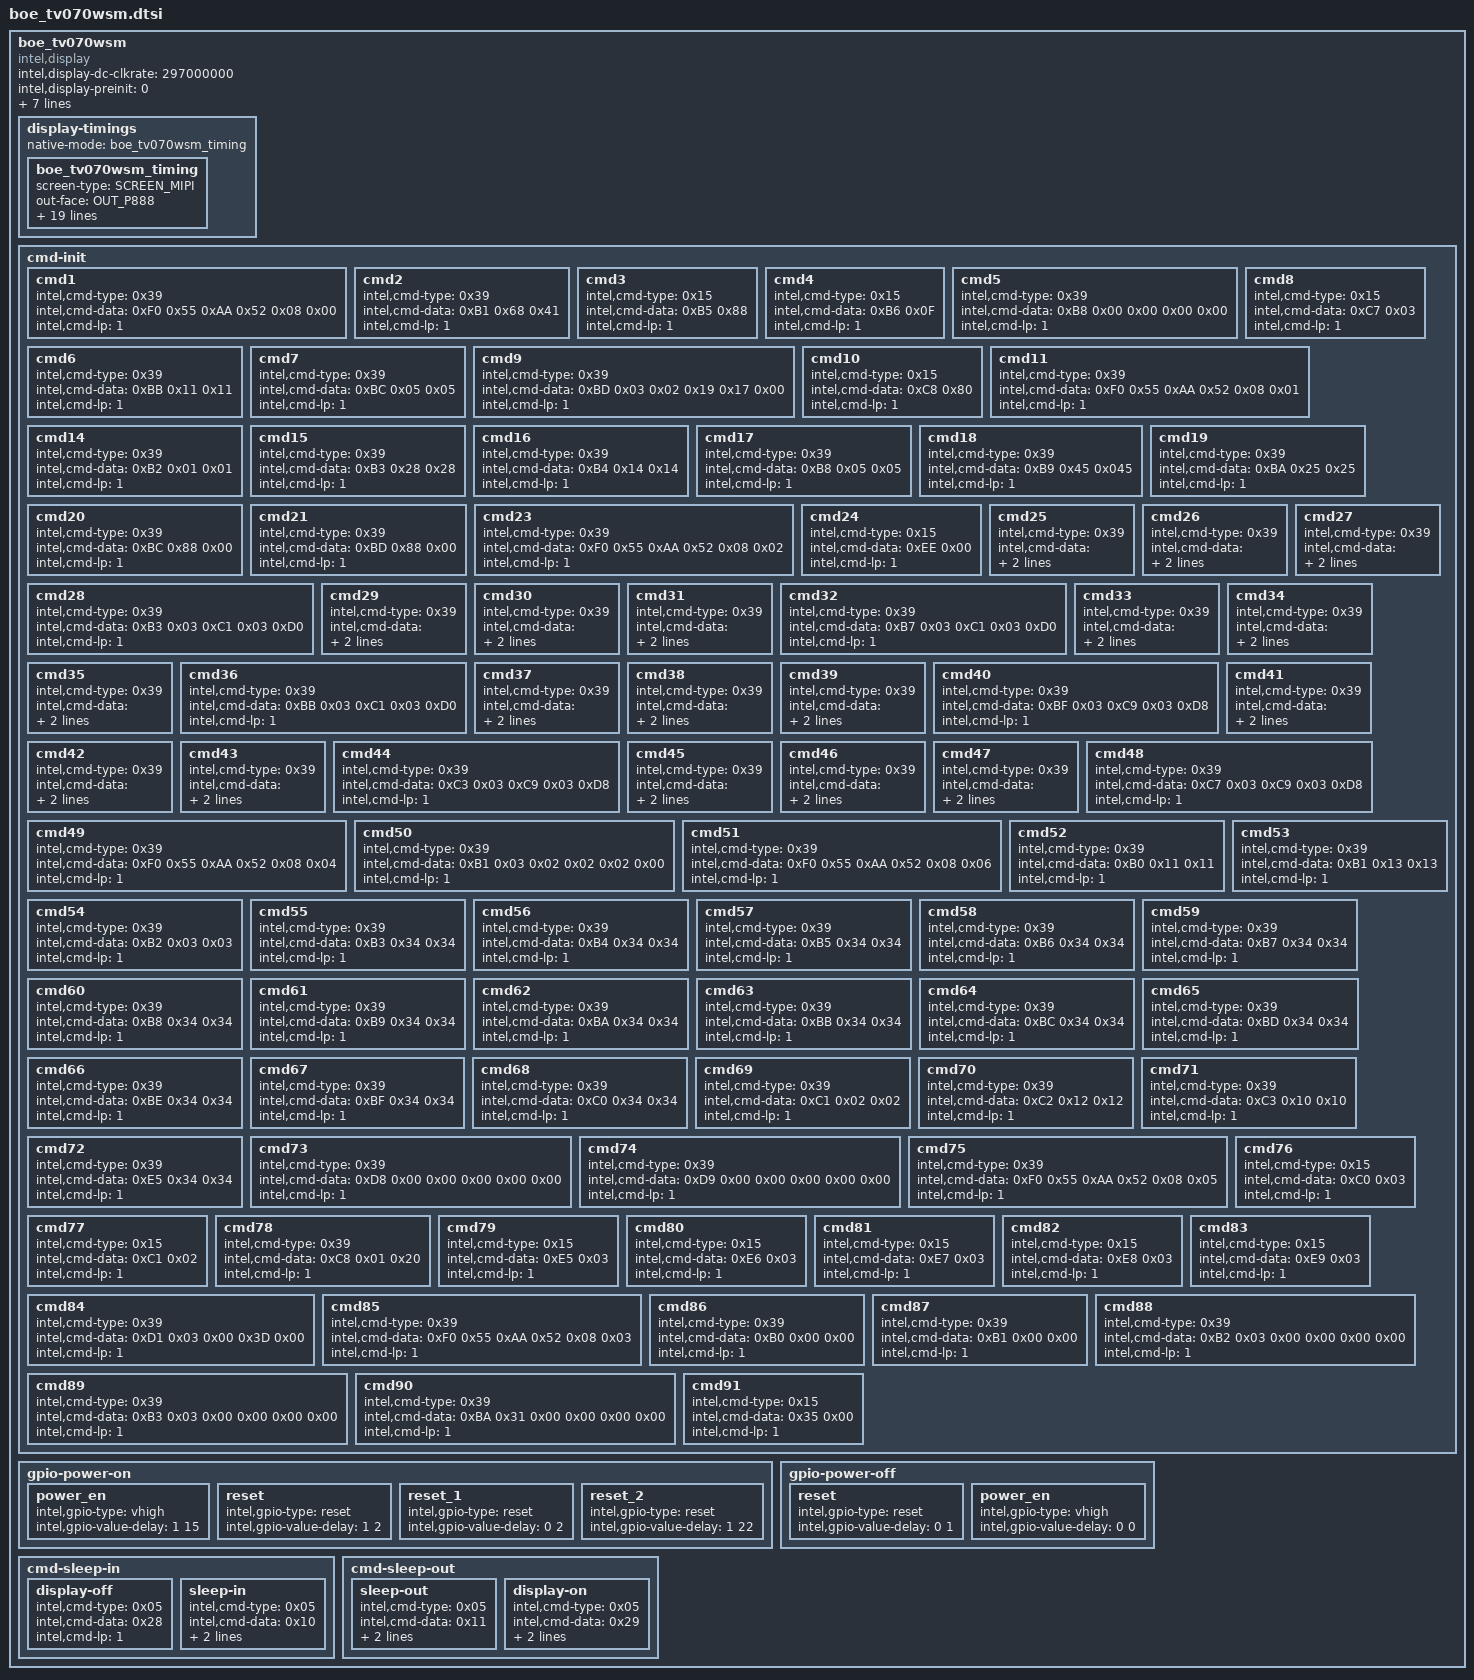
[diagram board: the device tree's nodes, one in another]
/*
 * definition at "include/dt-bindings/sofiafb/sofia_fb.h"
 */


boe_tv070wsm {
	compatible = "intel,display";
	intel,display-dc-clkrate = <297000000>;
	intel,display-preinit = <0>;
	intel,display-ramless = <1>;
	intel,display-fps = <60>;
	intel,display-vid-mode = "burst";
	intel,display-vid-id = <0>;
	intel,display-if-nblanes = <4>;
	intel,display-eot = <1>;
	intel,display-gate = <1>;

	display-timings {
		native-mode = <&boe_tv070wsm_timing>;
		boe_tv070wsm_timing: boe_tv070wsm_timing {
			screen-type = <SCREEN_MIPI>;
			out-face    = <OUT_P888>;
			color-mode = <COLOR_RGB>;
			width = <89>;
			height = <152>;
			clock-frequency = <42432000>;
			hactive = <600>;
			vactive = <1024>;
			hback-porch = <36>;
			hfront-porch = <20>;
			vback-porch = <8>;
			vfront-porch = <6>;
			hsync-len = <24>;
			vsync-len = <2>;
			hsync-active = <0>;
			vsync-active = <0>;
			de-active = <0>;
			pixelclk-active = <0>;
			swap-rb = <0>;
			swap-rg = <0>;
			swap-gb = <0>;
		};
	};
	cmd-init{
		cmd1 {
			intel,cmd-type = <0x39>;
			intel,cmd-data = <0xF0 0x55 0xAA 0x52 0x08 0x00>;
		        intel,cmd-lp = <1>;
		};
		cmd2 {
			intel,cmd-type = <0x39>;
			intel,cmd-data = <0xB1 0x68 0x41>;
			intel,cmd-lp = <1>;
		};
		cmd3 {
			intel,cmd-type = <0x15>;
			intel,cmd-data = <0xB5 0x88>;
			intel,cmd-lp = <1>;
		};
		cmd4 {
			intel,cmd-type = <0x15>;
			intel,cmd-data = <0xB6 0x0F>;
			intel,cmd-lp = <1>;
		};
		cmd5 {
			intel,cmd-type = <0x39>;
			intel,cmd-data = <0xB8 0x00 0x00 0x00 0x00>;
			intel,cmd-lp = <1>;
		};
		cmd6 {
			intel,cmd-type = <0x39>;
			intel,cmd-data = <0xBB 0x11 0x11>;
			intel,cmd-lp = <1>;
		};
		cmd7 {
			intel,cmd-type = <0x39>;
			intel,cmd-data = <0xBC 0x05 0x05>;
			intel,cmd-lp = <1>;
		};
		cmd8 {
			intel,cmd-type = <0x15>;
			intel,cmd-data = <0xC7 0x03>;
			intel,cmd-lp = <1>;
		};
		cmd9 {
			intel,cmd-type = <0x39>;
			intel,cmd-data = <0xBD 0x03 0x02 0x19 0x17 0x00>;
			intel,cmd-lp = <1>;
		};
		cmd10 {
			intel,cmd-type = <0x15>;
			intel,cmd-data = <0xC8 0x80>;
			intel,cmd-lp = <1>;
		};
		cmd11 {
			intel,cmd-type = <0x39>;
			intel,cmd-data = <0xF0 0x55 0xAA 0x52 0x08 0x01>;
			intel,cmd-lp = <1>;
		};
		cmd14 {
			intel,cmd-type = <0x39>;
			intel,cmd-data = <0xB2 0x01 0x01>;
			intel,cmd-lp = <1>;
		};
		cmd15 {
			intel,cmd-type = <0x39>;
			intel,cmd-data = <0xB3 0x28 0x28>;
			intel,cmd-lp = <1>;
		};
		cmd16 {
			intel,cmd-type = <0x39>;
			intel,cmd-data = <0xB4 0x14 0x14>;
			intel,cmd-lp = <1>;
		};
		cmd17 {
			intel,cmd-type = <0x39>;
			intel,cmd-data = <0xB8 0x05 0x05>;
			intel,cmd-lp = <1>;
		};
		cmd18 {
			intel,cmd-type = <0x39>;
			intel,cmd-data = <0xB9 0x45 0x045>;
			intel,cmd-lp = <1>;
		};
		cmd19 {
			intel,cmd-type = <0x39>;
			intel,cmd-data = <0xBA 0x25 0x25>;
			intel,cmd-lp = <1>;
		};
		cmd20 {
			intel,cmd-type = <0x39>;
			intel,cmd-data = <0xBC 0x88 0x00>;
			intel,cmd-lp = <1>;
		};
		cmd21 {
			intel,cmd-type = <0x39>;
			intel,cmd-data = <0xBD 0x88 0x00>;
			intel,cmd-lp = <1>;
		};
		cmd23 {
			intel,cmd-type = <0x39>;
			intel,cmd-data = <0xF0 0x55 0xAA 0x52 0x08 0x02>;
			intel,cmd-lp = <1>;
		};
		cmd24 {
			intel,cmd-type = <0x15>;
			intel,cmd-data = <0xEE 0x00>;
			intel,cmd-lp = <1>;
		};
		cmd25 {
			intel,cmd-type = <0x39>;
			intel,cmd-data = <0xB0 0x00 0x4E 0x00 0x51 0x00 0x77 0x00
			0x8F 0x00 0xA3 0x00 0xC6 0x00 0xE0
			0x01 0x12>;
			intel,cmd-lp = <1>;
		};
		cmd26 {
			intel,cmd-type = <0x39>;
			intel,cmd-data = <0xB1 0x01 0x34 0x01 0x6D 0x01 0x97 0x01
			0xDC 0x02 0x13 0x02 0x14 0x02 0x47
			0x02 0x7D>;
			intel,cmd-lp = <1>;
		};
		cmd27 {
			intel,cmd-type = <0x39>;
			intel,cmd-data = <0xB2 0x02 0xA5 0x02 0xD7 0x02 0xFA 0x03
			0x27 0x03 0x44 0x03 0x6D 0x03 0x8B
			0x03 0xA2>;
			intel,cmd-lp = <1>;
		};
		cmd28 {
			intel,cmd-type = <0x39>;
			intel,cmd-data = <0xB3 0x03 0xC1 0x03 0xD0>;
			intel,cmd-lp = <1>;
		};
		cmd29 {
			intel,cmd-type = <0x39>;
			intel,cmd-data = <0xB4 0x00 0x4E 0x00 0x51 0x00 0x77 0x00
			0x8F 0x00 0xA3 0x00 0xC6 0x00 0xE0
			0x01 0x12>;
			intel,cmd-lp = <1>;
		};
		cmd30 {
			intel,cmd-type = <0x39>;
			intel,cmd-data = <0xB5 0x01 0x34 0x01 0x6B 0x01 0x97 0x01
			0xDC 0x02 0x13 0x02 0x14 0x02 0x47
			0x02 0x7D>;
			intel,cmd-lp = <1>;
		};
		cmd31 {
			intel,cmd-type = <0x39>;
			intel,cmd-data = <0xB6 0x02 0xA5 0x02 0xD7 0x02 0xFA 0x03
			0x27 0x03 0x44 0x03 0x6D 0x03 0x8B
			0x03 0xA2>;
			intel,cmd-lp = <1>;
		};
		cmd32 {
			intel,cmd-type = <0x39>;
			intel,cmd-data = <0xB7 0x03 0xC1 0x03 0xD0>;
			intel,cmd-lp = <1>;
		};
		cmd33 {
			intel,cmd-type = <0x39>;
			intel,cmd-data = <0xB8 0x01 0x25 0x01 0x2E 0x01 0x3F 0x01
			0x42 0x01 0x49 0x01 0x56 0x01 0x67
			0x01 0x7A>;
			intel,cmd-lp = <1>;
		};
		cmd34 {
			intel,cmd-type = <0x39>;
			intel,cmd-data = <0xB9 0x01 0x8D 0x01 0xAA 0x01 0xC8 0x01
			0xFD 0x02 0x29 0x02 0x2A 0x02 0x58
			0x02 0x8F>;
			intel,cmd-lp = <1>;
		};
		cmd35 {
			intel,cmd-type = <0x39>;
			intel,cmd-data = <0xBA 0x02 0xB3 0x02 0xDE 0x03 0x03 0x03
			0x33 0x03 0x4A 0x03 0x6D 0x03 0x8B
			0x03 0xA2>;
			intel,cmd-lp = <1>;
		};
		cmd36 {
			intel,cmd-type = <0x39>;
			intel,cmd-data = <0xBB 0x03 0xC1 0x03 0xD0>;
			intel,cmd-lp = <1>;
		};
		cmd37 {
			intel,cmd-type = <0x39>;
			intel,cmd-data = <0xBC 0x00 0x34 0x00 0x37 0x00 0x61 0x00
			0x77 0x00 0x8D 0x00 0xB2 0x00 0xCE
			0x01 0x00>;
			intel,cmd-lp = <1>;
		};
		cmd38 {
			intel,cmd-type = <0x39>;
			intel,cmd-data = <0xBD 0x01 0x26 0x01 0x63 0x01 0x92 0x01
			0xDA 0x02 0x13 0x02 0x14 0x02 0x49
			0x02 0x7F>;
			intel,cmd-lp = <1>;
		};
		cmd39 {
			intel,cmd-type = <0x39>;
			intel,cmd-data = <0xBE 0x02 0xA7 0x02 0xDB 0x02 0xFE 0x03
			0x2B 0x03 0x48 0x03 0x73 0x03 0x91
			0x03 0xA8>;
			intel,cmd-lp = <1>;
		};
		cmd40 {
			intel,cmd-type = <0x39>;
			intel,cmd-data = <0xBF 0x03 0xC9 0x03 0xD8>;
			intel,cmd-lp = <1>;
		};
		cmd41 {
			intel,cmd-type = <0x39>;
			intel,cmd-data = <0xC0 0x00 0x34 0x00 0x37 0x00 0x61 0x00
			0x77 0x00 0x8D 0x00 0xB2 0x00 0xCE
			0x01 0x00>;
			intel,cmd-lp = <1>;
		};
		cmd42 {
			intel,cmd-type = <0x39>;
			intel,cmd-data = <0xC1 0x01 0x26 0x01 0x63 0x01 0x92 0x01
			0xDA 0x02 0x13 0x02 0x14 0x02 0x49
			0x02 0x7F>;
			intel,cmd-lp = <1>;
		};
		cmd43 {
			intel,cmd-type = <0x39>;
			intel,cmd-data = <0xC2 0x02 0xA7 0x02 0xDB 0x02 0xFE 0x03
			0x2B 0x03 0x48 0x03 0x73 0x03 0x91
			0x03 0xA8>;
			intel,cmd-lp = <1>;
		};
		cmd44 {
			intel,cmd-type = <0x39>;
			intel,cmd-data = <0xC3 0x03 0xC9 0x03 0xD8>;
			intel,cmd-lp = <1>;
		};
		cmd45 {
			intel,cmd-type = <0x39>;
			intel,cmd-data = <0xC4 0x01 0x0B 0x01 0x14 0x01 0x27 0x01
			0x2A 0x01 0x33 0x01 0x42 0x01 0x53
			0x01 0x69>;
			intel,cmd-lp = <1>;
		};
		cmd46 {
			intel,cmd-type = <0x39>;
			intel,cmd-data = <0xC5 0x01 0x7F 0x01 0xA0 0x01 0xBF 0x01
			0xFB 0x02 0x29 0x02 0x2A 0x02 0x5A
			0x02 0x91>;
			intel,cmd-lp = <1>;
		};
		cmd47 {
			intel,cmd-type = <0x39>;
			intel,cmd-data = <0xC6 0x02 0xB5 0x02 0xE2 0x03 0x07 0x03
			0x37 0x03 0x4E 0x03 0x73 0x03 0x91
			0x03 0xA8>;
			intel,cmd-lp = <1>;
		};
		cmd48 {
			intel,cmd-type = <0x39>;
			intel,cmd-data = <0xC7 0x03 0xC9 0x03 0xD8>;
			intel,cmd-lp = <1>;
		};
		cmd49 {
			intel,cmd-type = <0x39>;
			intel,cmd-data = <0xF0 0x55 0xAA 0x52 0x08 0x04>;
			intel,cmd-lp = <1>;
		};
		cmd50 {
			intel,cmd-type = <0x39>;
			intel,cmd-data = <0xB1 0x03 0x02 0x02 0x02 0x00>;
			intel,cmd-lp = <1>;
		};
		cmd51 {
			intel,cmd-type = <0x39>;
			intel,cmd-data = <0xF0 0x55 0xAA 0x52 0x08 0x06>;
			intel,cmd-lp = <1>;
		};
		cmd52 {
			intel,cmd-type = <0x39>;
			intel,cmd-data = <0xB0 0x11 0x11>;
			intel,cmd-lp = <1>;
		};
		cmd53 {
			intel,cmd-type = <0x39>;
			intel,cmd-data = <0xB1 0x13 0x13>;
			intel,cmd-lp = <1>;
		};
		cmd54 {
			intel,cmd-type = <0x39>;
			intel,cmd-data = <0xB2 0x03 0x03>;
			intel,cmd-lp = <1>;
		};
		cmd55 {
			intel,cmd-type = <0x39>;
			intel,cmd-data = <0xB3 0x34 0x34>;
			intel,cmd-lp = <1>;
		};
		cmd56 {
			intel,cmd-type = <0x39>;
			intel,cmd-data = <0xB4 0x34 0x34>;
			intel,cmd-lp = <1>;
		};
		cmd57 {
			intel,cmd-type = <0x39>;
			intel,cmd-data = <0xB5 0x34 0x34>;
			intel,cmd-lp = <1>;
		};
		cmd58 {
			intel,cmd-type = <0x39>;
			intel,cmd-data = <0xB6 0x34 0x34>;
			intel,cmd-lp = <1>;
		};
		cmd59 {
			intel,cmd-type = <0x39>;
			intel,cmd-data = <0xB7 0x34 0x34>;
			intel,cmd-lp = <1>;
		};
		cmd60 {
			intel,cmd-type = <0x39>;
			intel,cmd-data = <0xB8 0x34 0x34>;
			intel,cmd-lp = <1>;
		};
		cmd61 {
			intel,cmd-type = <0x39>;
			intel,cmd-data = <0xB9 0x34 0x34>;
			intel,cmd-lp = <1>;
		};
		cmd62 {
			intel,cmd-type = <0x39>;
			intel,cmd-data = <0xBA 0x34 0x34>;
			intel,cmd-lp = <1>;
		};
		cmd63 {
			intel,cmd-type = <0x39>;
			intel,cmd-data = <0xBB 0x34 0x34>;
			intel,cmd-lp = <1>;
		};
		cmd64 {
			intel,cmd-type = <0x39>;
			intel,cmd-data = <0xBC 0x34 0x34>;
			intel,cmd-lp = <1>;
		};
		cmd65 {
			intel,cmd-type = <0x39>;
			intel,cmd-data = <0xBD 0x34 0x34>;
			intel,cmd-lp = <1>;
		};
		cmd66 {
			intel,cmd-type = <0x39>;
			intel,cmd-data = <0xBE 0x34 0x34>;
			intel,cmd-lp = <1>;
		};
		cmd67 {
			intel,cmd-type = <0x39>;
			intel,cmd-data = <0xBF 0x34 0x34>;
			intel,cmd-lp = <1>;
		};
		cmd68 {
			intel,cmd-type = <0x39>;
			intel,cmd-data = <0xC0 0x34 0x34>;
			intel,cmd-lp = <1>;
		};
		cmd69 {
			intel,cmd-type = <0x39>;
			intel,cmd-data = <0xC1 0x02 0x02>;
			intel,cmd-lp = <1>;
		};
		cmd70 {
			intel,cmd-type = <0x39>;
			intel,cmd-data = <0xC2 0x12 0x12>;
			intel,cmd-lp = <1>;
		};
		cmd71 {
			intel,cmd-type = <0x39>;
			intel,cmd-data = <0xC3 0x10 0x10>;
			intel,cmd-lp = <1>;
		};
		cmd72 {
			intel,cmd-type = <0x39>;
			intel,cmd-data = <0xE5 0x34 0x34>;
			intel,cmd-lp = <1>;
		};
		cmd73 {
			intel,cmd-type = <0x39>;
			intel,cmd-data = <0xD8 0x00 0x00 0x00 0x00 0x00>;
			intel,cmd-lp = <1>;
		};
		cmd74 {
			intel,cmd-type = <0x39>;
			intel,cmd-data = <0xD9 0x00 0x00 0x00 0x00 0x00>;
			intel,cmd-lp = <1>;
		};
		cmd75 {
			intel,cmd-type = <0x39>;
			intel,cmd-data = <0xF0 0x55 0xAA 0x52 0x08 0x05>;
			intel,cmd-lp = <1>;
		};
		cmd76 {
			intel,cmd-type = <0x15>;
			intel,cmd-data = <0xC0 0x03>;
			intel,cmd-lp = <1>;
		};
		cmd77 {
			intel,cmd-type = <0x15>;
			intel,cmd-data = <0xC1 0x02>;
			intel,cmd-lp = <1>;
		};
		cmd78 {
			intel,cmd-type = <0x39>;
			intel,cmd-data = <0xC8 0x01 0x20>;
			intel,cmd-lp = <1>;
		};
		cmd79 {
			intel,cmd-type = <0x15>;
			intel,cmd-data = <0xE5 0x03>;
			intel,cmd-lp = <1>;
		};
		cmd80 {
			intel,cmd-type = <0x15>;
			intel,cmd-data = <0xE6 0x03>;
			intel,cmd-lp = <1>;
		};
		cmd81 {
			intel,cmd-type = <0x15>;
			intel,cmd-data = <0xE7 0x03>;
			intel,cmd-lp = <1>;
		};
		cmd82 {
			intel,cmd-type = <0x15>;
			intel,cmd-data = <0xE8 0x03>;
			intel,cmd-lp = <1>;
		};
		cmd83 {
			intel,cmd-type = <0x15>;
			intel,cmd-data = <0xE9 0x03>;
			intel,cmd-lp = <1>;
		};
		cmd84 {
			intel,cmd-type = <0x39>;
			intel,cmd-data = <0xD1 0x03 0x00 0x3D 0x00>;
			intel,cmd-lp = <1>;
		};
		cmd85 {
			intel,cmd-type = <0x39>;
			intel,cmd-data = <0xF0 0x55 0xAA 0x52 0x08 0x03>;
			intel,cmd-lp = <1>;
		};
		cmd86 {
			intel,cmd-type = <0x39>;
			intel,cmd-data = <0xB0 0x00 0x00>;
			intel,cmd-lp = <1>;
		};
		cmd87 {
			intel,cmd-type = <0x39>;
			intel,cmd-data = <0xB1 0x00 0x00>;
			intel,cmd-lp = <1>;
		};
		cmd88 {
			intel,cmd-type = <0x39>;
			intel,cmd-data = <0xB2 0x03 0x00 0x00 0x00 0x00>;
			intel,cmd-lp = <1>;
		};
		cmd89 {
			intel,cmd-type = <0x39>;
			intel,cmd-data = <0xB3 0x03 0x00 0x00 0x00 0x00>;
			intel,cmd-lp = <1>;
		};
		cmd90 {
			intel,cmd-type = <0x39>;
			intel,cmd-data = <0xBA 0x31 0x00 0x00 0x00 0x00>;
			intel,cmd-lp = <1>;
		};
		cmd91 {
			intel,cmd-type = <0x15>;
			intel,cmd-data = <0x35 0x00>;
			intel,cmd-lp = <1>;
		};
	/*
		cmdbist1 {
			intel,cmd-type = <0x39>;
			intel,cmd-data = <0xF0 0x55 0xAA 0x52 0x08 0x00>;
			intel,cmd-lp = <1>;
		};
		cmdbist2 {
			intel,cmd-type = <0x39>;
			intel,cmd-data = <0xEE 0x87 0x78 0x02 0x40>;
			intel,cmd-lp = <1>;
		};
		cmdbist3 {
			intel,cmd-type = <0x39>;
			intel,cmd-data = <0xEF 0x00 0xFF 0xFF 0xFF>;
			intel,cmd-lp = <1>;
		};
	*/
	};
	gpio-power-on {
		power_en {
				intel,gpio-type = "vhigh";
				intel,gpio-value-delay = <1 15>;
		};
		reset {
			intel,gpio-type = "reset";
			intel,gpio-value-delay = <1 2>;
		};

		reset_1 {
			intel,gpio-type = "reset";
			intel,gpio-value-delay = <0 2>;
		};
		reset_2 {
			intel,gpio-type = "reset";
			intel,gpio-value-delay = <1 22>;
		};
	};

	gpio-power-off {
		reset {
			intel,gpio-type = "reset";
			intel,gpio-value-delay = <0 1>;
		};
		power_en {
			intel,gpio-type = "vhigh";
			intel,gpio-value-delay = <0 0>;
		};
	};

	cmd-sleep-in {
		display-off{
			intel,cmd-type = <0x05>;
			intel,cmd-data = <0x28>;
			intel,cmd-lp = <1>;
		};
		sleep-in{
			intel,cmd-type = <0x05>;
			intel,cmd-data = <0x10>;
			intel,cmd-delay = <84>;
			intel,cmd-lp = <1>;
		};
	};

	cmd-sleep-out {
		sleep-out{
			intel,cmd-type = <0x05>;
			intel,cmd-data = <0x11>;
			intel,cmd-delay = <130>;
			intel,cmd-lp = <1>;
		};
		display-on{
			intel,cmd-type = <0x05>;
			intel,cmd-data = <0x29>;
			intel,cmd-delay = <32>;
			intel,cmd-lp = <1>;
		};
	};
};
